# R7KA8D2AD register map
Vendor: Renesas Electronics Corporation; Series: RA8; File version: 1.10.02
CPU: CM85 r0p2, little endian, MPU, FPU, VTOR, 4 interrupt priority bits, 96 interrupts
Registers are 32-bit, read-write, reset 0x0 unless marked. A register's access mark holds for its fields unless they carry their own. Offsets are from the block's base; [hi:lo] are bit positions; {n}, {i} and the like mark numbered series.

## MIPI_CSI0 — MIPI_CSI0 Register area
Base 0x40347000
Same registers: MIPI_CSI0_NS 0x50347000
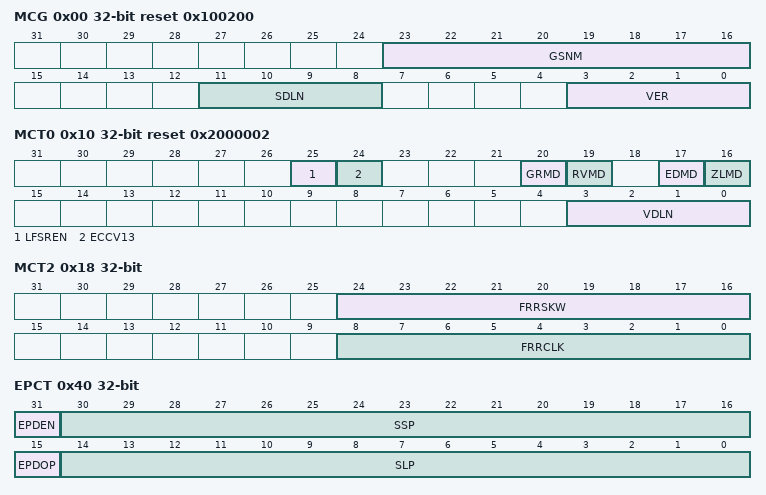
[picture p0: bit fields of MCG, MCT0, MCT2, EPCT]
0x00 MCG ro reset 0x100200 — Module Configuration Register
  [23:16] GSNM — Number of Generic Short Packet FIFO
  [11:8] SDLN — Number of Supported Data Lanes
    2=Operable with 2 lanes or 1 lane
  [3:0] VER — Version of this IP
0x10 MCT0 reset 0x2000002 — Module Control Register 0
  [25] LFSREN — LFSR Enable Mode
    0=Disables descrambling; 1=Enables descrambling
  [24] ECCV13 — ECC Check CSI-2 Ver 1.3 Mode
    0=26 bits to be checked for ECC; 1=24 bits to be checked for ECC
  [20] GRMD — Generic CSI-2 Rule Mode
  [19] RVMD — Reserved Packet Reception Mode
    0=Discards the data (notifies an ErrID); 1=Receives data as a long packet (outputs data to Video Pixel interface when the corresponding bit in DTEH is 1, or discards the data and notifies an ErrID when the corresponding bit in DTEH is 0)
  [17] EDMD — ErrframeData Notification Mode
    0=Does not notify ErrFrameData; 1=Notifies ErrFrameData
  [16] ZLMD — Zero Length Long Packet Output Mode
    0=Output; 1=No output
  [3:0] VDLN — Number of Valid Data Lanes
    1=Operation with one lane; 2=Operation with two lanes; other=Others (Setting prohibited)
0x18 MCT2 — Module Control Register 2
  [24:16] FRRSKW — Frequency clock rate to adjust data lane skew (internal setting parameter)
  [8:0] FRRCLK — Frequency clock rate to determine packet reception end (internal setting parameter)
0x1C MCT3 — Module Control Register 3
  [0] RXEN — RX (reception) Enable
    0=Disables reception; 1=Enables reception
0x28 RTCT wo — Reset Control Register
  [0] VSRST — Video Pixel Interface Software Reset
0x2C RTST ro — Reset Status Register
  [0] VSRSTS — Video Pixel Interface Software Reset Status
    0=Does not indicate status during a reset; 1=Indicates status during a reset
0x40 EPCT — EPD Option Control Register
  [31] EPDEN — Enable EPD Operation
    0=Disables the EPD; 1=Enables the EPD
  [30:16] SSP — EPD Short Packet Spacers
  [15] EPDOP — EPD Option Select
    0=D-PHY EPD Option 1 (0 cannot be set when EPDEN = 1); 1=D-PHY EPD Option 2
  [14:0] SLP — Long Packet Spacers
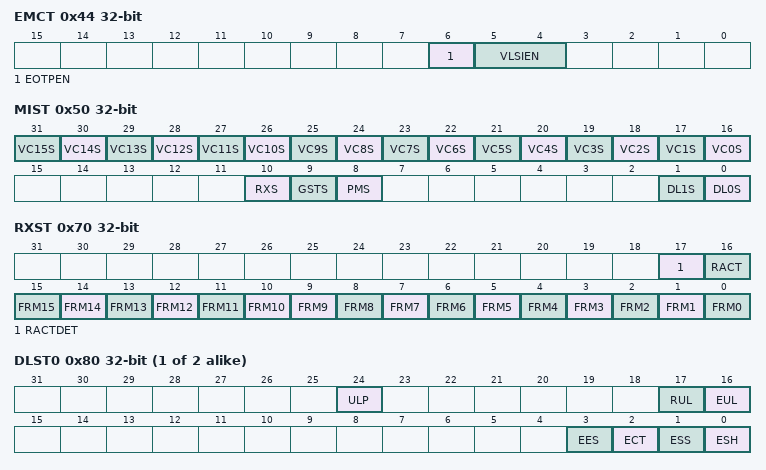
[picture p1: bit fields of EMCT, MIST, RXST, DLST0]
0x44 EMCT — EPD Misc Option Control Register
  [6] EOTPEN — Enable EOTP
    0=No EOTP; 1=With EOTP
  [5:4] VLSIEN — Enable Variable Length Spacer Insertions
    0=Variable length spacer invalid (spacer number is fixed length); 1=Variable length spacer valid (spacer number is 1 × n/lane); 2=Variable length spacer valid (spacer number is 2 × n/lane); 3=Variable length spacer valid (spacer number is 4 × n/lane)
0x50 MIST ro — Module Interrupt Status Register
  [n+16] VC{n}S (n=0..15) — Interrupt status of virtual channel {n}
  [10] RXS — Interrupt status of RX (reception)
  [9] GSTS — Interrupt status of generic short packet
  [8] PMS — Interrupt status of power management
  [1] DL1S — Interrupt status of data lane 1
  [0] DL0S — Interrupt status of data lane 0
0x60 DTEL reset 0xF — Receive Data Type Enable Low Register
  [31:0] DTEN — Data Type Enable (DT = 0x00 to 0x1F)
    0=Does not receive data; 1=Receives data
0x64 DTEH — Receive Data Type Enable High Register
  [31:0] DTEN — Data Type Enable (DT = 0x20 to 0x3F)
    0=Does not receive data; 1=Receives data
0x70 RXST ro — Receive Status Register
  [17] RACTDET — RX (Reception) Active Detect
  [16] RACT — Rx (Reception) active status
  [n] FRM{n} (n=10..15) — Frame of virtual channel {n} active
  [9] FRM9 — FRaMe of virtual channel 9 active
  [n] FRM{n} (n=0..8) — Frame of virtual channel {n} active
0x74 RXSC wo — Receive Status Clear Register
  [17] RACTDETC — RX (Reception) Active Detect Status Clear
0x78 RXIE — Receive Interrupt Enable Register
  [17] RACTDETE — RX (Reception) Active Detect Interrupt Enable
    0=Does not assert csi2_int_rx when RXST.RACTDET = 1; 1=Asserts csi2_int_rx when RXST.RACTDET = 1
{0x80+0x10*i} DLST{i} (i=0..1) ro — Data Lane (N) Status Register
  [24] ULP — RxULPsesc of data lane (N) status
  [17] RUL — Entry to ULPS detect on data lane (N) status
  [16] EUL — Exit from ULps detect on data lane (N) status
  [3] EES — ErrESc detect on data lane (N) status
  [2] ECT — ErrConTrol detect on data lane (N) status
  [1] ESS — ErrSotSynchs detect on data lane (N) status
  [0] ESH — ErrSotHs detect on data lane (N) status
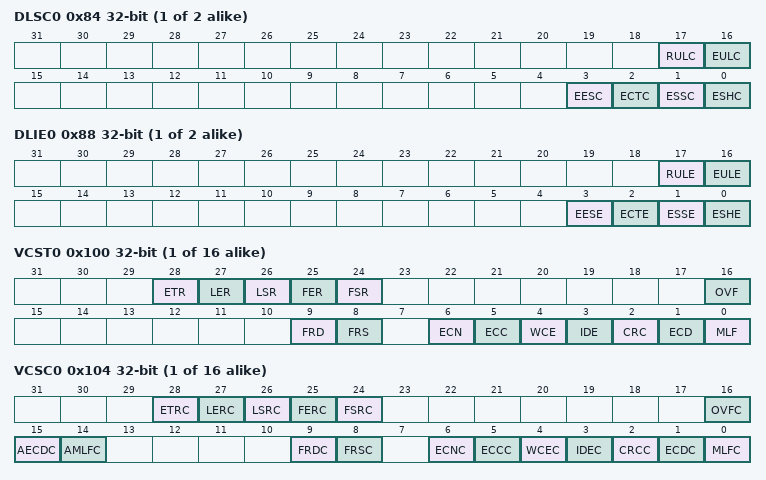
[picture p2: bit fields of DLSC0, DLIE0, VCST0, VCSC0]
{0x84+0x10*i} DLSC{i} (i=0..1) wo — Data Lane (N) Status Clear Register
  [17] RULC — Entry to ULps detect on data lane (N) status Clear
  [16] EULC — Exit from ULps detect on data lane (N) status Clear
  [3] EESC — ErrESc detect on data lane (N) status Clear
  [2] ECTC — ErrConTrol detect on data lane (N) status Clear
  [1] ESSC — ErrSotSynchs detect on data lane (N) status Clear
  [0] ESHC — ErrSotHs detect on data lane (N) status Clear
{0x88+0x10*i} DLIE{i} (i=0..1) — Data Lane (N) Interrupt Enable Register
  [17] RULE — Entry to ULps detect on data lane (N) interrupt Enable
    0=Does not assert csi2_int_dl when DLST(N).RUL = 1; 1=Asserts csi2_int_dl when DLST(N).RUL = 1
  [16] EULE — Exit to ULps detect on data lane (N) interrupt Enable
    0=Does not assert csi2_int_dl when DLST(N).EUL = 1; 1=Asserts csi2_int_dl when DLST(N).EUL = 1
  [3] EESE — ErrESc detect on data lane (N) interrupt Enable
    0=Does not assert csi2_int_dl when DLST(N).EES = 1; 1=Asserts csi2_int_dl when DLST(N).EES = 1
  [2] ECTE — ErrConTrol detect on data lane (N) interrupt Enable
    0=Does not assert csi2_int_dl when DLST(N).ECT = 1; 1=Asserts csi2_int_dl when DLST(N).ECT = 1
  [1] ESSE — ErrSotSynchs detect on data lane (N) interrupt Enable
    0=Does not assert csi2_int_dl when DLST(N).ESS = 1; 1=Asserts csi2_int_dl when DLST(N).ESS = 1
  [0] ESHE — ErrSotHs detect on data lane (N) interrupt Enable
    0=Does not assert csi2_int_dl when DLST(N).ESH = 1; 1=Asserts csi2_int_dl when DLST(N).ESH = 1
{0x100+0x10*i} VCST{i} (i=0..15) ro — Virtual Channel (M) Status Register
  [28] ETR — EoTp packet with virtual channel (M) Reception status
  [27] LER — Line End packet with virtual channel (M) Reception status
  [26] LSR — Line Start packet with virtual channel (M) Reception status
  [25] FER — Frame End packet with virtual channel (M) Reception status
  [24] FSR — Frame Start packet with virtual channel (M) Reception status
  [16] OVF — generic short packet with virtual channel (M) discard by fifo OVerFlow status
  [9] FRD — errFRameData of virtual channel (M) detect status
  [8] FRS — errFRameSync of virtual channel (M) detect status
  [6] ECN — ECc No-error packet with virtual channel (M) detect status
  [5] ECC — ECc 1-bit error (Corrected) packet with virtual channel (M) detect status
  [4] WCE — Word Count Error packet with virtual channel (M) detect status
  [3] IDE — ErrID packet with virtual channel (M) detect status
  [2] CRC — CRC error packet with virtual channel (M) detect status
  [1] ECD — ECc 2-bit (Double) error packet with virtual channel (M) Detect status
  [0] MLF — MaLFormed packet with virtual channel (M) detect status
{0x104+0x10*i} VCSC{i} (i=0..15) wo — Virtual Channel (M) Status Clear Register
  [28] ETRC — EoTp packet with virtual channel (M) Reception status Clear
  [27] LERC — Line End packet with virtual channel (M) Reception status Clear
  [26] LSRC — Line Start packet with virtual channel (M) Reception status Clear
  [25] FERC — Frame End packet with virtual channel (M) Reception status Clear
  [24] FSRC — Frame Start packet with virtual channel (M) Reception status Clear
  [16] OVFC — Generic short packet with virtual channel (M) discard by FIFO Overflow Status Clear
  [15] AECDC — ECc 2-bit (Double) error packet with any virtual channels Detect status Clear
  [14] AMLFC — MaLFormed packet with any virtual channels detect status Clear
  [9] FRDC — errFRameData of virtual channel (M) detect status Clear
  [8] FRSC — errFRameSync of virtual channel (M) detect status Clear
  [6] ECNC — ECc No-error packet with virtual channel (M) detect status Clear
  [5] ECCC — ECc 1-bit error (Corrected) packet with virtual channel (M) detect status Clear
  [4] WCEC — Word Count Error packet with virtual channel (M) detect status Clear
  [3] IDEC — ErrID packet with virtual channel (M) detect status Clear
  [2] CRCC — CRC error packet with virtual channel (M) detect status Clear
  [1] ECDC — ECc 2-bit (Double) error packet with virtual channel (M) Detect status Clear
  [0] MLFC — MaLFormed packet with virtual channel (M) detect status Clear
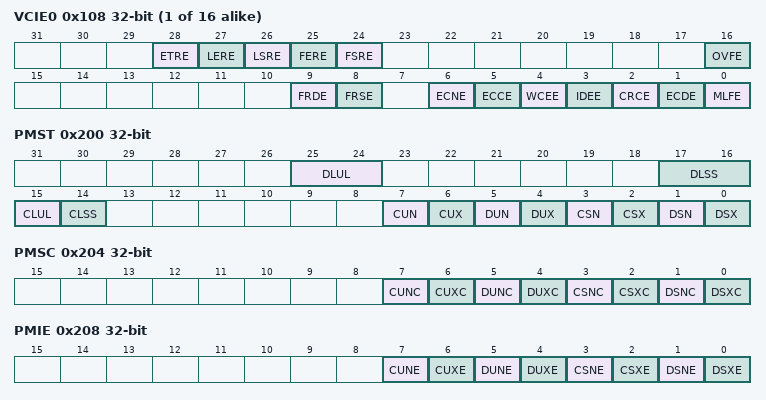
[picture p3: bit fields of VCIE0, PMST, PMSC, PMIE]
{0x108+0x10*i} VCIE{i} (i=0..15) — Virtual Channel (M) Interrupt Enable Register
  [28] ETRE — EoTp packet with virtual channel (M) Reception interrupt Enable
    0=Does not assert csi2_int_vc when VCST(M).ETR = 1; 1=Asserts csi2_int_vc when VCST(M).ETR = 1
  [27] LERE — Line End packet with virtual channel (M) Reception interrupt Enable
    0=Does not assert csi2_int_vc when VCST(M).LER = 1; 1=Asserts csi2_int_vc when VCST(M).LER = 1
  [26] LSRE — Line Start packet with virtual channel (M) Reception interrupt Enable
    0=Does not assert csi2_int_vc when VCST(M).LSR = 1; 1=Asserts csi2_int_vc when VCST(M).LSR = 1
  [25] FERE — Frame End packet with virtual channel (M) Reception interrupt Enable
    0=Does not assert csi2_int_vc when VCST(M).FER = 1; 1=Asserts csi2_int_vc when VCST(M).FER = 1
  [24] FSRE — Frame Start packet with virtual channel (M) Reception interrupt Enable
    0=Does not assert csi2_int_vc when VCST(M).FSR = 1; 1=Asserts csi2_int_vc when VCST(M).FSR = 1
  [16] OVFE — Generic short packet with virtual channel (M) discarded by FIFO Overflow interrupt Enable
    0=Does not assert csi2_int_vc when VCST(M).OVF = 1; 1=Asserts csi2_int_vc when VCST(M).OVF = 1
  [9] FRDE — errFRameData of virtual channel (M) detect interrupt Enable
    0=Does not assert csi2_int_vc when VCST(M).FRD = 1; 1=Asserts csi2_int_vc when VCST(M).FRD = 1
  [8] FRSE — errFRameSync of virtual channel (M) detect interrupt Enable
    0=Does not assert csi2_int_vc when VCST(M).FRS = 1; 1=Asserts csi2_int_vc when VCST(M).FRS = 1
  [6] ECNE — ECc No-error packet with virtual channel (M) detect interrupt Enable
    0=Does not assert csi2_int_vc when VCST(M).ECN = 1; 1=Asserts csi2_int_vc when VCST(M).ECN = 1
  [5] ECCE — ECc 1-bit error (Corrected) packet with virtual channel (M) detect interrupt Enable
    0=Does not assert csi2_int_vc when VCST(M).ECC = 1; 1=Asserts csi2_int_vc when VCST(M).ECC = 1
  [4] WCEE — Word Count Error packet with virtual channel (M) detect interrupt Enable
    0=Does not assert csi2_int_vc when VCST(M).WCE = 1; 1=Asserts csi2_int_vc when VCST(M).WCE = 1
  [3] IDEE — ErrID packet with virtual channel (M) detect interrupt Enable
    0=Does not assert csi2_int_vc when VCST(M).IDE = 1; 1=Asserts csi2_int_vc when VCST(M).IDE = 1
  [2] CRCE — CRC error packet with virtual channel (M) detect interrupt Enable
    0=Does not assert csi2_int_vc when VCST(M).CRC = 1; 1=Asserts csi2_int_vc when VCST(M).CRC = 1
  [1] ECDE — ECc 2-bit (Double) error packet with virtual channel (M) Detect interrupt Enable
    0=Does not assert csi2_int_vc when VCST(M).ECD = 1; 1=Asserts csi2_int_vc when VCST(M).ECD = 1
  [0] MLFE — MaLFormed packet with virtual channel (M) detect interrupt Enable
    0=Does not assert csi2_int_vc when VCST(M).MLF = 1; 1=Asserts csi2_int_vc when VCST(M).MLF = 1
0x200 PMST ro (reset mask 0xFFFF7FFF) — Power Management Status Register
  [25:24] DLUL — rxULpsesc of Data Lanes status
    0=RxUlpsEsc of lane 0; 1=RxUlpsEsc of lane 1
  [17:16] DLSS — Stop State of Data Lanes status
    0=Stop state of lane 0; 1=Stop state of lane 1
  [15] CLUL — rxULpsclknot (inverted) of Clock Lane status
    0=Not in ULPS; 1=In ULPS
  [14] CLSS — Stop State of Clock Lane status
    0=Not in the stop state; 1=In the stop state
  [7] CUN — eNtry to Ulps detect on Clock lane status
  [6] CUX — eXit from Ulps detect on Clock lane status
  [5] DUN — eNtry to Ulps detect on all valid Data lanes status
  [4] DUX — eXit from Ulps detect on all valid Data lanes status
  [3] CSN — eNtry to Stop state detect on Clock lane status
  [2] CSX — eXit from Stop state detect on Clock lane status
  [1] DSN — eNtry to Stop state detect on all valid Data lanes status
  [0] DSX — eXit from Stop state detect on all valid Data lanes status
0x204 PMSC wo — Power Management Status Clear Register
  [7] CUNC — eNtry to Ulps detect on Clock lane status Clear
  [6] CUXC — eXit from Ulps detect on Clock lane status Clear
  [5] DUNC — eNtry to Ulps detect on all valid Data lanes status Clear
  [4] DUXC — eXit from Ulps detect on all valid Data lanes status Clear
  [3] CSNC — eNtry to Stop state detect on Clock lane status Clear
  [2] CSXC — eXit from Stop state detect on Clock lane status Clear
  [1] DSNC — eNtry to Stop state detect on all valid Data lanes status Clear
  [0] DSXC — eXit from Stop state detect on all valid Data lanes status Clear
0x208 PMIE — Power Management Interrupt Enable Register
  [7] CUNE — eNtry to Ulps detect on Clock lane interrupt Enable
    0=Does not assert csi2_int_pm when PMST.CUN = 1; 1=Asserts csi2_int_pm when PMST.CUN = 1
  [6] CUXE — eXit from Ulps detect on Clock lane interrupt Enable
    0=Does not assert csi2_int_pm when PMST.CUX = 1; 1=Asserts csi2_int_pm when PMST.CUX = 1
  [5] DUNE — eNtry to Ulps detect on all valid Data lanes interrupt Enable
    0=Does not assert csi2_int_pm when PMST.DUN = 1; 1=Asserts csi2_int_pm when PMST.DUN = 1
  [4] DUXE — eXit from Ulps detect on all valid Data lanes interrupt Enable
    0=Does not assert csi2_int_pm when PMST.DUX = 1; 1=Asserts csi2_int_pm when PMST.DUX = 1
  [3] CSNE — eNtry to Stop state detect on Clock lane interrupt Enable
    0=Does not assert csi2_int_pm when PMST.CSN = 1; 1=Asserts csi2_int_pm when PMST.CSN = 1
  [2] CSXE — eXit from Stop state detect on Clock lane interrupt Enable
    0=Does not assert csi2_int_pm when PMST.CSX = 1; 1=Asserts csi2_int_pm when PMST.CSX = 1
  [1] DSNE — eNtry to Stop state detect on all valid Data lanes interrupt Enable
    0=Does not assert csi2_int_pm when PMST.DSN = 1; 1=Asserts csi2_int_pm when PMST.DSN = 1
  [0] DSXE — eXit from Stop state detect on all valid Data lanes interrupt Enable
    0=Does not assert csi2_int_pm when PMST.DSX = 1; 1=Asserts csi2_int_pm when PMST.DSX = 1
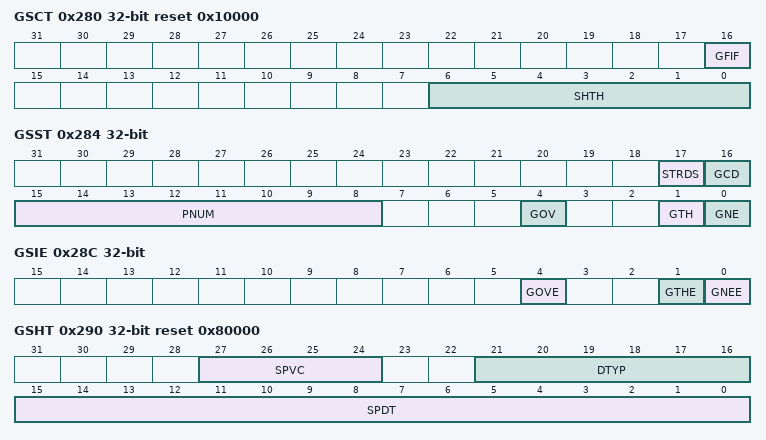
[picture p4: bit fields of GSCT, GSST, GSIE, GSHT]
0x280 GSCT reset 0x10000 — Generic Short Packet Control Register
  [16] GFIF — Generic short packet store in FIFO
  [6:0] SHTH — Stored generic short packet THreshold
0x284 GSST ro — Generic Short Packet Status Register
  [17] STRDS — Generic short packet SToRe DiSable
    0=Can be stored in the generic short packet FIFO; 1=Cannot be stored in the generic short packet FIFO
  [16] GCD — Generic short packet FIFO Clear status
  [15:8] PNUM — NUMber of stored generic short Packets in FIFO
  [4] GOV — Generic short packet fifo OVerflow status
  [1] GTH — More than THreshold Generic short packets existed in FIFO
  [0] GNE — Generic short packet FIFO Not Empty
0x288 GSSC wo — Generic Short Packet Status Clear Register
  [4] GOVC — Generic short packet FIFO OVerflow status Clear
0x28C GSIE — Generic Short Packet Interrupt Enable Register
  [4] GOVE — Generic short packet FIFO OVerflow interrupt Enable
    0=Does not assert csi2_int_gst when GSST.GOV = 1; 1=Asserts csi2_int_gst when GSST.GOV = 1
  [1] GTHE — More than THreshold Generic short packets existed in FIFO interrupt Enable
    0=Does not assert csi2_int_gst when GSST.GTH = 1; 1=Asserts csi2_int_gst when GSST.GTH = 1
  [0] GNEE — Generic short packet FIFO Not Empty interrupt Enable
    0=Does not assert csi2_int_gst when GSST.GNE = 1; 1=Asserts csi2_int_gst when GSST.GNE = 1
0x290 GSHT ro reset 0x80000 — Generic Short Packet Register
  [27:24] SPVC — Stored Packet Virtual Channel
  [21:16] DTYP — Stored packet Data TYPe
  [15:0] SPDT — Stored Packet DaTa
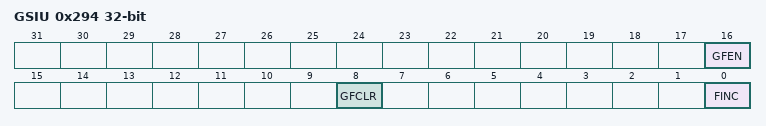
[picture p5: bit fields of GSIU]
0x294 GSIU — Generic Short Packet Information Update Register
  [16] GFEN wo — Generic short packet FIFO ENable
  [8] GFCLR — Generic short packet FIFO CLeaR
  [0] FINC wo — Generic short packet FIFO update (INCrement internal pointer)
